VERSION ""

NS_ :

BS_:

BU_: C70 PIT IRTEMP

BO_ 384 PIT_Pressures: 8 PIT
 SG_ PIT_PressureMux M : 0|8@1+ (1,0) [0|255] "" Vector__XXX
 SG_ PIT_Pressure1 m0 : 15|16@0+ (0.01,600) [600|1200] "mbar" Vector__XXX
 SG_ PIT_Pressure2 m0 : 31|16@0+ (0.01,600) [600|1200] "mbar" Vector__XXX
 SG_ PIT_Pressure3 m0 : 47|16@0+ (0.01,600) [600|1200] "mbar" Vector__XXX
 SG_ PIT_PressureRange m0 : 56|8@1+ (1,0) [0|3] "" Vector__XXX
 SG_ PIT_Pressure4 m1 : 15|16@0+ (0.01,600) [600|1200] "mbar" Vector__XXX
 SG_ PIT_Pressure5 m1 : 31|16@0+ (0.01,600) [600|1200] "mbar" Vector__XXX
 SG_ PIT_Pressure6 m1 : 47|16@0+ (0.01,600) [600|1200] "mbar" Vector__XXX
 SG_ PIT_Temperature m1 : 56|8@1- (1,0) [0|0] "degC" Vector__XXX
 SG_ PIT_Pressure7 m2 : 15|16@0+ (0.01,600) [600|1200] "mbar" Vector__XXX
 SG_ PIT_Pressure8 m2 : 31|16@0+ (0.01,600) [600|1200] "mbar" Vector__XXX
 SG_ PIT_SensorNum m2 : 47|16@0+ (1,0) [0|0] "" Vector__XXX

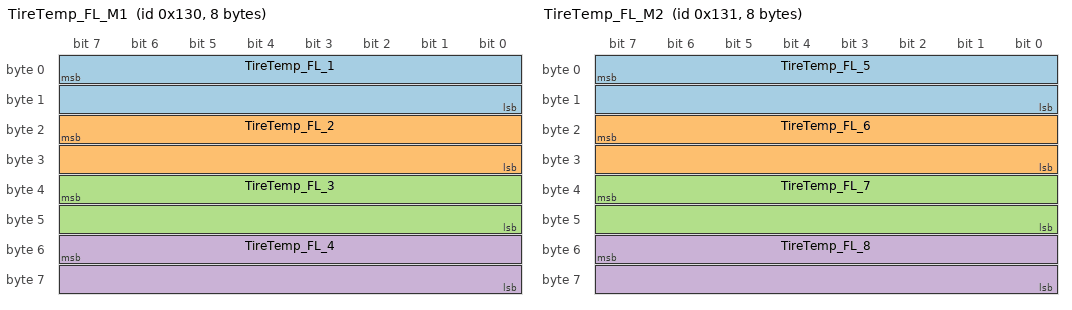
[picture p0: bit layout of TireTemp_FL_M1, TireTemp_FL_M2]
BO_ 304 TireTemp_FL_M1: 8 IRTEMP
 SG_ TireTemp_FL_1 : 7|16@0+ (0.1,-100) [-20|950] "degC" Vector__XXX
 SG_ TireTemp_FL_2 : 23|16@0+ (0.1,-100) [-20|950] "degC" Vector__XXX
 SG_ TireTemp_FL_3 : 39|16@0+ (0.1,-100) [-20|950] "degC" Vector__XXX
 SG_ TireTemp_FL_4 : 55|16@0+ (0.1,-100) [-20|950] "degC" Vector__XXX

BO_ 305 TireTemp_FL_M2: 8 IRTEMP
 SG_ TireTemp_FL_5 : 7|16@0+ (0.1,-100) [-20|950] "degC" Vector__XXX
 SG_ TireTemp_FL_6 : 23|16@0+ (0.1,-100) [-20|950] "degC" Vector__XXX
 SG_ TireTemp_FL_7 : 39|16@0+ (0.1,-100) [-20|950] "degC" Vector__XXX
 SG_ TireTemp_FL_8 : 55|16@0+ (0.1,-100) [-20|950] "degC" Vector__XXX

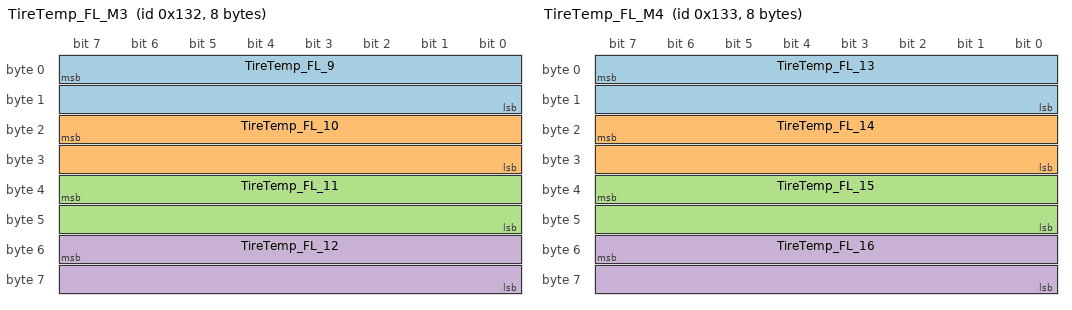
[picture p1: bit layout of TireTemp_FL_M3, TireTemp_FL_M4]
BO_ 306 TireTemp_FL_M3: 8 IRTEMP
 SG_ TireTemp_FL_9 : 7|16@0+ (0.1,-100) [-20|950] "degC" Vector__XXX
 SG_ TireTemp_FL_10 : 23|16@0+ (0.1,-100) [-20|950] "degC" Vector__XXX
 SG_ TireTemp_FL_11 : 39|16@0+ (0.1,-100) [-20|950] "degC" Vector__XXX
 SG_ TireTemp_FL_12 : 55|16@0+ (0.1,-100) [-20|950] "degC" Vector__XXX

BO_ 307 TireTemp_FL_M4: 8 IRTEMP
 SG_ TireTemp_FL_13 : 7|16@0+ (0.1,-100) [-20|950] "degC" Vector__XXX
 SG_ TireTemp_FL_14 : 23|16@0+ (0.1,-100) [-20|950] "degC" Vector__XXX
 SG_ TireTemp_FL_15 : 39|16@0+ (0.1,-100) [-20|950] "degC" Vector__XXX
 SG_ TireTemp_FL_16 : 55|16@0+ (0.1,-100) [-20|950] "degC" Vector__XXX

BO_ 308 TireTemp_FL_M5: 8 IRTEMP
 SG_ TireTemp_FL_Sensor : 7|16@0+ (0.1,-100) [-20|85] "degC" Vector__XXX

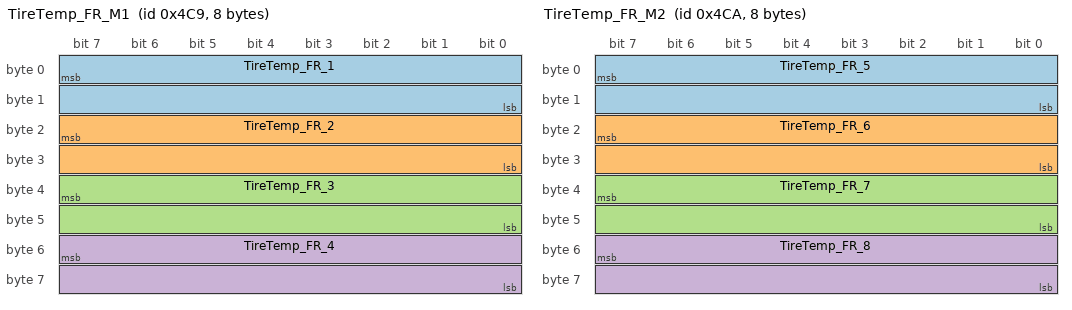
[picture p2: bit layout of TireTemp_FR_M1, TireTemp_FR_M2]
BO_ 1225 TireTemp_FR_M1: 8 IRTEMP
 SG_ TireTemp_FR_1 : 7|16@0+ (0.1,-100) [-20|950] "degC" Vector__XXX
 SG_ TireTemp_FR_2 : 23|16@0+ (0.1,-100) [-20|950] "degC" Vector__XXX
 SG_ TireTemp_FR_3 : 39|16@0+ (0.1,-100) [-20|950] "degC" Vector__XXX
 SG_ TireTemp_FR_4 : 55|16@0+ (0.1,-100) [-20|950] "degC" Vector__XXX

BO_ 1226 TireTemp_FR_M2: 8 IRTEMP
 SG_ TireTemp_FR_5 : 7|16@0+ (0.1,-100) [-20|950] "degC" Vector__XXX
 SG_ TireTemp_FR_6 : 23|16@0+ (0.1,-100) [-20|950] "degC" Vector__XXX
 SG_ TireTemp_FR_7 : 39|16@0+ (0.1,-100) [-20|950] "degC" Vector__XXX
 SG_ TireTemp_FR_8 : 55|16@0+ (0.1,-100) [-20|950] "degC" Vector__XXX

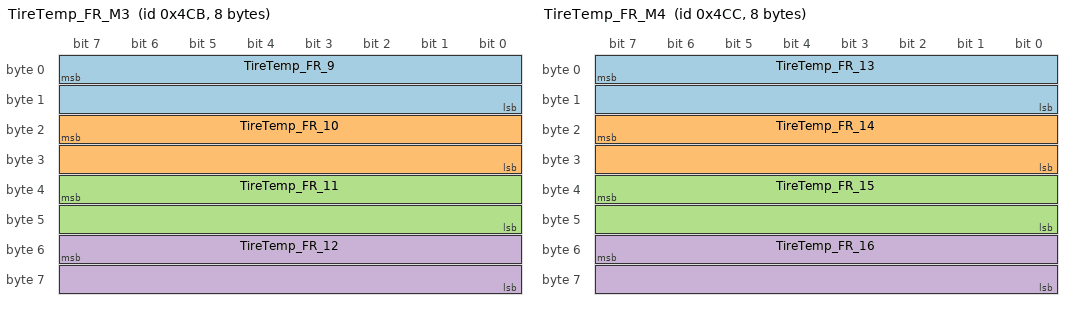
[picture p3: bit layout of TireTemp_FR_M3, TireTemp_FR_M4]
BO_ 1227 TireTemp_FR_M3: 8 IRTEMP
 SG_ TireTemp_FR_9 : 7|16@0+ (0.1,-100) [-20|950] "degC" Vector__XXX
 SG_ TireTemp_FR_10 : 23|16@0+ (0.1,-100) [-20|950] "degC" Vector__XXX
 SG_ TireTemp_FR_11 : 39|16@0+ (0.1,-100) [-20|950] "degC" Vector__XXX
 SG_ TireTemp_FR_12 : 55|16@0+ (0.1,-100) [-20|950] "degC" Vector__XXX

BO_ 1228 TireTemp_FR_M4: 8 IRTEMP
 SG_ TireTemp_FR_13 : 7|16@0+ (0.1,-100) [-20|950] "degC" Vector__XXX
 SG_ TireTemp_FR_14 : 23|16@0+ (0.1,-100) [-20|950] "degC" Vector__XXX
 SG_ TireTemp_FR_15 : 39|16@0+ (0.1,-100) [-20|950] "degC" Vector__XXX
 SG_ TireTemp_FR_16 : 55|16@0+ (0.1,-100) [-20|950] "degC" Vector__XXX

BO_ 1229 TireTemp_FR_M5: 8 IRTEMP
 SG_ TireTemp_FR_Sensor : 7|16@0+ (0.1,-100) [-20|85] "degC" Vector__XXX

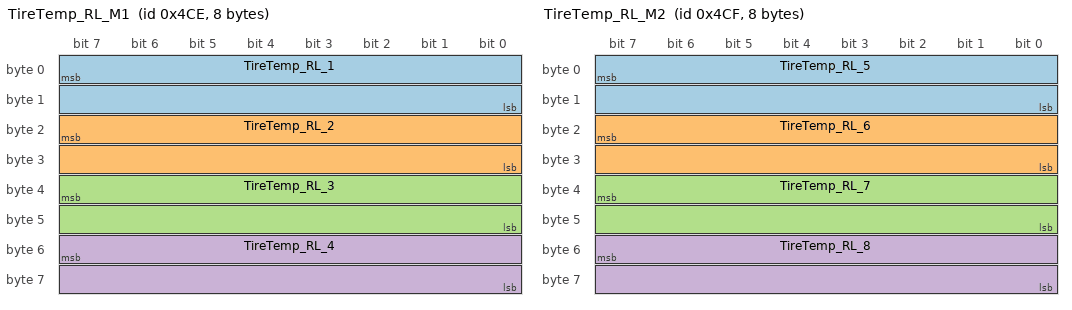
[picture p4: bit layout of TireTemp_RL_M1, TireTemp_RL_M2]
BO_ 1230 TireTemp_RL_M1: 8 IRTEMP
 SG_ TireTemp_RL_1 : 7|16@0+ (0.1,-100) [-20|950] "degC" Vector__XXX
 SG_ TireTemp_RL_2 : 23|16@0+ (0.1,-100) [-20|950] "degC" Vector__XXX
 SG_ TireTemp_RL_3 : 39|16@0+ (0.1,-100) [-20|950] "degC" Vector__XXX
 SG_ TireTemp_RL_4 : 55|16@0+ (0.1,-100) [-20|950] "degC" Vector__XXX

BO_ 1231 TireTemp_RL_M2: 8 IRTEMP
 SG_ TireTemp_RL_5 : 7|16@0+ (0.1,-100) [-20|950] "degC" Vector__XXX
 SG_ TireTemp_RL_6 : 23|16@0+ (0.1,-100) [-20|950] "degC" Vector__XXX
 SG_ TireTemp_RL_7 : 39|16@0+ (0.1,-100) [-20|950] "degC" Vector__XXX
 SG_ TireTemp_RL_8 : 55|16@0+ (0.1,-100) [-20|950] "degC" Vector__XXX

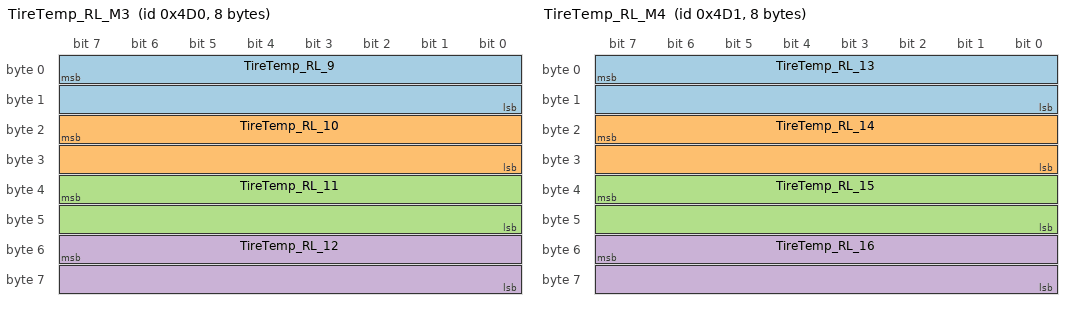
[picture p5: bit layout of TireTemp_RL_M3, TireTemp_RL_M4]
BO_ 1232 TireTemp_RL_M3: 8 IRTEMP
 SG_ TireTemp_RL_9 : 7|16@0+ (0.1,-100) [-20|950] "degC" Vector__XXX
 SG_ TireTemp_RL_10 : 23|16@0+ (0.1,-100) [-20|950] "degC" Vector__XXX
 SG_ TireTemp_RL_11 : 39|16@0+ (0.1,-100) [-20|950] "degC" Vector__XXX
 SG_ TireTemp_RL_12 : 55|16@0+ (0.1,-100) [-20|950] "degC" Vector__XXX

BO_ 1233 TireTemp_RL_M4: 8 IRTEMP
 SG_ TireTemp_RL_13 : 7|16@0+ (0.1,-100) [-20|950] "degC" Vector__XXX
 SG_ TireTemp_RL_14 : 23|16@0+ (0.1,-100) [-20|950] "degC" Vector__XXX
 SG_ TireTemp_RL_15 : 39|16@0+ (0.1,-100) [-20|950] "degC" Vector__XXX
 SG_ TireTemp_RL_16 : 55|16@0+ (0.1,-100) [-20|950] "degC" Vector__XXX

BO_ 1234 TireTemp_RL_M5: 8 IRTEMP
 SG_ TireTemp_RL_Sensor : 7|16@0+ (0.1,-100) [-20|85] "degC" Vector__XXX

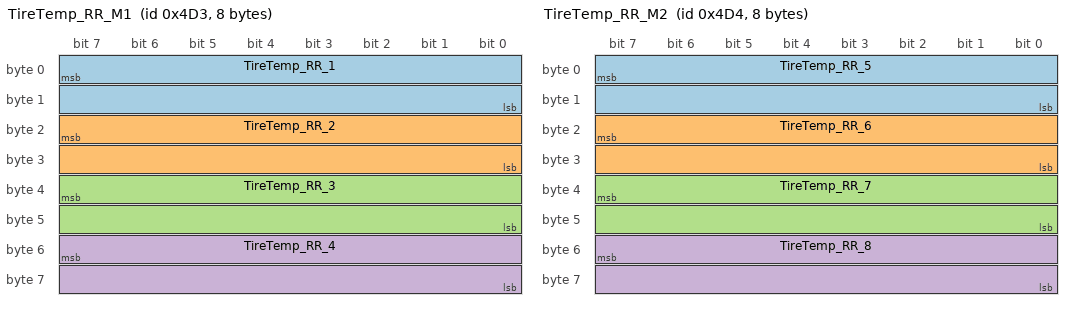
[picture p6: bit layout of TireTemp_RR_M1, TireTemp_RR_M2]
BO_ 1235 TireTemp_RR_M1: 8 IRTEMP
 SG_ TireTemp_RR_1 : 7|16@0+ (0.1,-100) [-20|950] "degC" Vector__XXX
 SG_ TireTemp_RR_2 : 23|16@0+ (0.1,-100) [-20|950] "degC" Vector__XXX
 SG_ TireTemp_RR_3 : 39|16@0+ (0.1,-100) [-20|950] "degC" Vector__XXX
 SG_ TireTemp_RR_4 : 55|16@0+ (0.1,-100) [-20|950] "degC" Vector__XXX

BO_ 1236 TireTemp_RR_M2: 8 IRTEMP
 SG_ TireTemp_RR_5 : 7|16@0+ (0.1,-100) [-20|950] "degC" Vector__XXX
 SG_ TireTemp_RR_6 : 23|16@0+ (0.1,-100) [-20|950] "degC" Vector__XXX
 SG_ TireTemp_RR_7 : 39|16@0+ (0.1,-100) [-20|950] "degC" Vector__XXX
 SG_ TireTemp_RR_8 : 55|16@0+ (0.1,-100) [-20|950] "degC" Vector__XXX

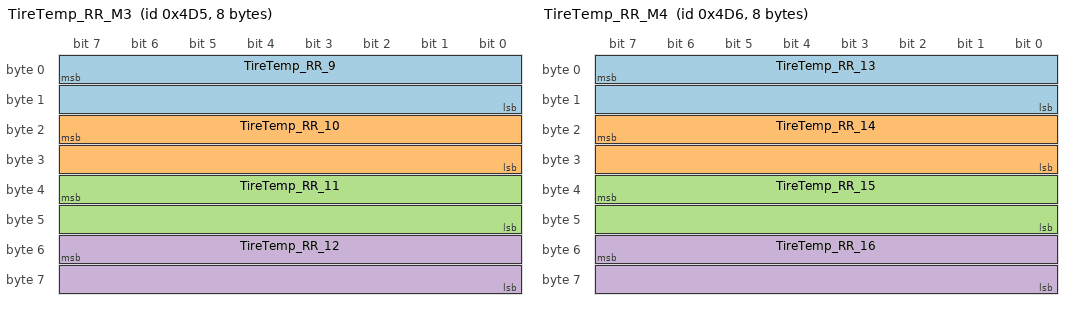
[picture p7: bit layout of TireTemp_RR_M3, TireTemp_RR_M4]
BO_ 1237 TireTemp_RR_M3: 8 IRTEMP
 SG_ TireTemp_RR_9 : 7|16@0+ (0.1,-100) [-20|950] "degC" Vector__XXX
 SG_ TireTemp_RR_10 : 23|16@0+ (0.1,-100) [-20|950] "degC" Vector__XXX
 SG_ TireTemp_RR_11 : 39|16@0+ (0.1,-100) [-20|950] "degC" Vector__XXX
 SG_ TireTemp_RR_12 : 55|16@0+ (0.1,-100) [-20|950] "degC" Vector__XXX

BO_ 1238 TireTemp_RR_M4: 8 IRTEMP
 SG_ TireTemp_RR_13 : 7|16@0+ (0.1,-100) [-20|950] "degC" Vector__XXX
 SG_ TireTemp_RR_14 : 23|16@0+ (0.1,-100) [-20|950] "degC" Vector__XXX
 SG_ TireTemp_RR_15 : 39|16@0+ (0.1,-100) [-20|950] "degC" Vector__XXX
 SG_ TireTemp_RR_16 : 55|16@0+ (0.1,-100) [-20|950] "degC" Vector__XXX

BO_ 1239 TireTemp_RR_M5: 8 IRTEMP
 SG_ TireTemp_RR_Sensor : 7|16@0+ (0.1,-100) [-20|85] "degC" Vector__XXX

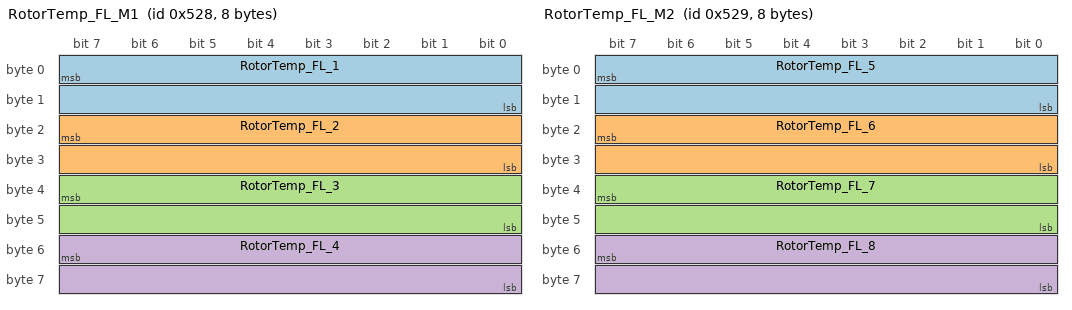
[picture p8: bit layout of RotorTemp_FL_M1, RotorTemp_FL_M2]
BO_ 1320 RotorTemp_FL_M1: 8 IRTEMP
 SG_ RotorTemp_FL_1 : 7|16@0+ (0.1,-100) [-20|950] "degC" Vector__XXX
 SG_ RotorTemp_FL_2 : 23|16@0+ (0.1,-100) [-20|950] "degC" Vector__XXX
 SG_ RotorTemp_FL_3 : 39|16@0+ (0.1,-100) [-20|950] "degC" Vector__XXX
 SG_ RotorTemp_FL_4 : 55|16@0+ (0.1,-100) [-20|950] "degC" Vector__XXX

BO_ 1321 RotorTemp_FL_M2: 8 IRTEMP
 SG_ RotorTemp_FL_5 : 7|16@0+ (0.1,-100) [-20|950] "degC" Vector__XXX
 SG_ RotorTemp_FL_6 : 23|16@0+ (0.1,-100) [-20|950] "degC" Vector__XXX
 SG_ RotorTemp_FL_7 : 39|16@0+ (0.1,-100) [-20|950] "degC" Vector__XXX
 SG_ RotorTemp_FL_8 : 55|16@0+ (0.1,-100) [-20|950] "degC" Vector__XXX

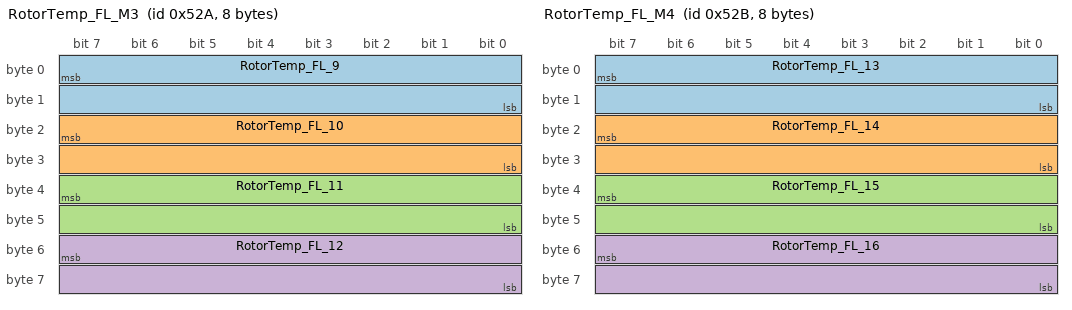
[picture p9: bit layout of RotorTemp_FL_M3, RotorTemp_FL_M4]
BO_ 1322 RotorTemp_FL_M3: 8 IRTEMP
 SG_ RotorTemp_FL_9 : 7|16@0+ (0.1,-100) [-20|950] "degC" Vector__XXX
 SG_ RotorTemp_FL_10 : 23|16@0+ (0.1,-100) [-20|950] "degC" Vector__XXX
 SG_ RotorTemp_FL_11 : 39|16@0+ (0.1,-100) [-20|950] "degC" Vector__XXX
 SG_ RotorTemp_FL_12 : 55|16@0+ (0.1,-100) [-20|950] "degC" Vector__XXX

BO_ 1323 RotorTemp_FL_M4: 8 IRTEMP
 SG_ RotorTemp_FL_13 : 7|16@0+ (0.1,-100) [-20|950] "degC" Vector__XXX
 SG_ RotorTemp_FL_14 : 23|16@0+ (0.1,-100) [-20|950] "degC" Vector__XXX
 SG_ RotorTemp_FL_15 : 39|16@0+ (0.1,-100) [-20|950] "degC" Vector__XXX
 SG_ RotorTemp_FL_16 : 55|16@0+ (0.1,-100) [-20|950] "degC" Vector__XXX

BO_ 1324 RotorTemp_FL_M5: 8 IRTEMP
 SG_ RotorTemp_FL_Sensor : 7|16@0+ (0.1,-100) [-20|85] "degC" Vector__XXX

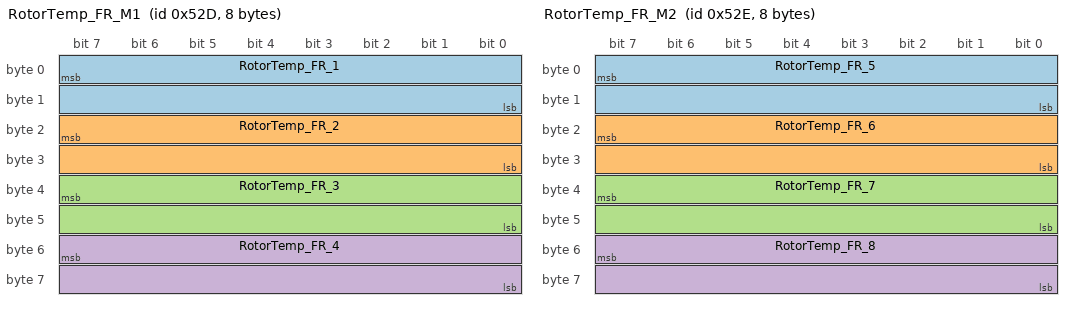
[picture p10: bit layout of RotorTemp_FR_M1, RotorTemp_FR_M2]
BO_ 1325 RotorTemp_FR_M1: 8 IRTEMP
 SG_ RotorTemp_FR_1 : 7|16@0+ (0.1,-100) [-20|950] "degC" Vector__XXX
 SG_ RotorTemp_FR_2 : 23|16@0+ (0.1,-100) [-20|950] "degC" Vector__XXX
 SG_ RotorTemp_FR_3 : 39|16@0+ (0.1,-100) [-20|950] "degC" Vector__XXX
 SG_ RotorTemp_FR_4 : 55|16@0+ (0.1,-100) [-20|950] "degC" Vector__XXX

BO_ 1326 RotorTemp_FR_M2: 8 IRTEMP
 SG_ RotorTemp_FR_5 : 7|16@0+ (0.1,-100) [-20|950] "degC" Vector__XXX
 SG_ RotorTemp_FR_6 : 23|16@0+ (0.1,-100) [-20|950] "degC" Vector__XXX
 SG_ RotorTemp_FR_7 : 39|16@0+ (0.1,-100) [-20|950] "degC" Vector__XXX
 SG_ RotorTemp_FR_8 : 55|16@0+ (0.1,-100) [-20|950] "degC" Vector__XXX

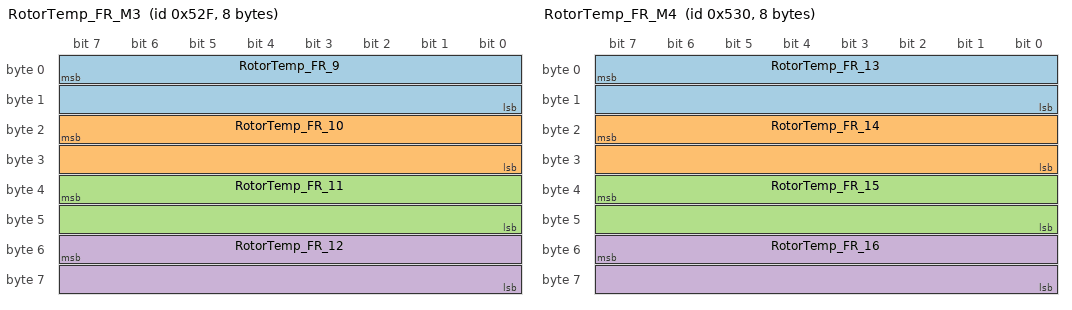
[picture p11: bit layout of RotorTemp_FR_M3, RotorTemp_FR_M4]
BO_ 1327 RotorTemp_FR_M3: 8 IRTEMP
 SG_ RotorTemp_FR_9 : 7|16@0+ (0.1,-100) [-20|950] "degC" Vector__XXX
 SG_ RotorTemp_FR_10 : 23|16@0+ (0.1,-100) [-20|950] "degC" Vector__XXX
 SG_ RotorTemp_FR_11 : 39|16@0+ (0.1,-100) [-20|950] "degC" Vector__XXX
 SG_ RotorTemp_FR_12 : 55|16@0+ (0.1,-100) [-20|950] "degC" Vector__XXX

BO_ 1328 RotorTemp_FR_M4: 8 IRTEMP
 SG_ RotorTemp_FR_13 : 7|16@0+ (0.1,-100) [-20|950] "degC" Vector__XXX
 SG_ RotorTemp_FR_14 : 23|16@0+ (0.1,-100) [-20|950] "degC" Vector__XXX
 SG_ RotorTemp_FR_15 : 39|16@0+ (0.1,-100) [-20|950] "degC" Vector__XXX
 SG_ RotorTemp_FR_16 : 55|16@0+ (0.1,-100) [-20|950] "degC" Vector__XXX

BO_ 1329 RotorTemp_FR_M5: 8 IRTEMP
 SG_ RotorTemp_FR_Sensor : 7|16@0+ (0.1,-100) [-20|85] "degC" Vector__XXX

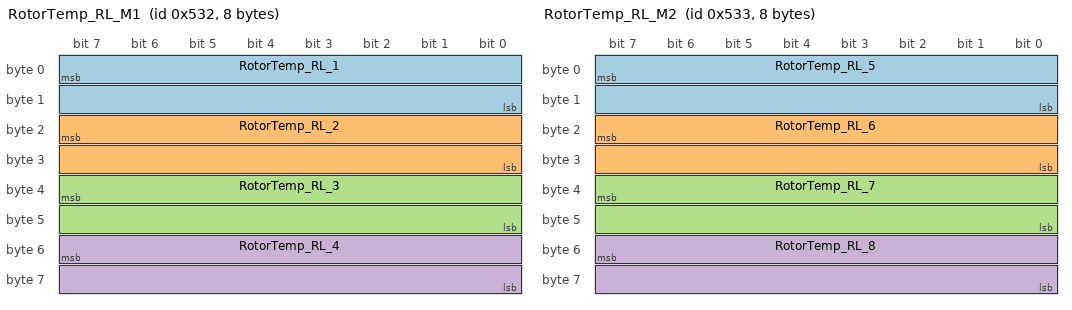
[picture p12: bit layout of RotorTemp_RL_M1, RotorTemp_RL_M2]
BO_ 1330 RotorTemp_RL_M1: 8 IRTEMP
 SG_ RotorTemp_RL_1 : 7|16@0+ (0.1,-100) [-20|950] "degC" Vector__XXX
 SG_ RotorTemp_RL_2 : 23|16@0+ (0.1,-100) [-20|950] "degC" Vector__XXX
 SG_ RotorTemp_RL_3 : 39|16@0+ (0.1,-100) [-20|950] "degC" Vector__XXX
 SG_ RotorTemp_RL_4 : 55|16@0+ (0.1,-100) [-20|950] "degC" Vector__XXX

BO_ 1331 RotorTemp_RL_M2: 8 IRTEMP
 SG_ RotorTemp_RL_5 : 7|16@0+ (0.1,-100) [-20|950] "degC" Vector__XXX
 SG_ RotorTemp_RL_6 : 23|16@0+ (0.1,-100) [-20|950] "degC" Vector__XXX
 SG_ RotorTemp_RL_7 : 39|16@0+ (0.1,-100) [-20|950] "degC" Vector__XXX
 SG_ RotorTemp_RL_8 : 55|16@0+ (0.1,-100) [-20|950] "degC" Vector__XXX

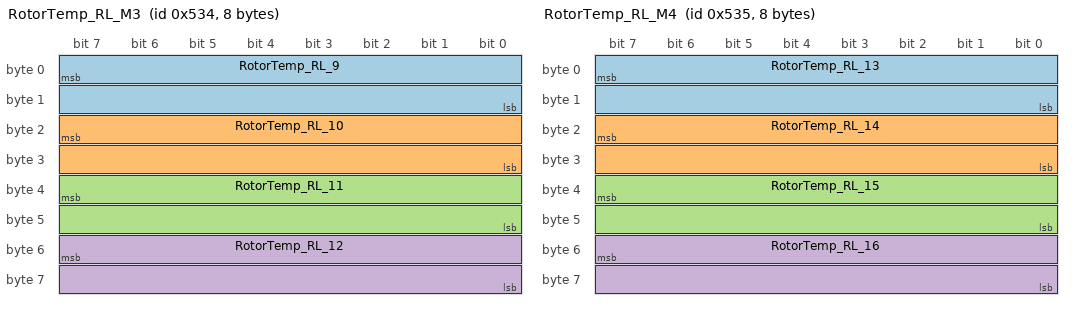
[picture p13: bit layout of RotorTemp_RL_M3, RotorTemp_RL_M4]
BO_ 1332 RotorTemp_RL_M3: 8 IRTEMP
 SG_ RotorTemp_RL_9 : 7|16@0+ (0.1,-100) [-20|950] "degC" Vector__XXX
 SG_ RotorTemp_RL_10 : 23|16@0+ (0.1,-100) [-20|950] "degC" Vector__XXX
 SG_ RotorTemp_RL_11 : 39|16@0+ (0.1,-100) [-20|950] "degC" Vector__XXX
 SG_ RotorTemp_RL_12 : 55|16@0+ (0.1,-100) [-20|950] "degC" Vector__XXX

BO_ 1333 RotorTemp_RL_M4: 8 IRTEMP
 SG_ RotorTemp_RL_13 : 7|16@0+ (0.1,-100) [-20|950] "degC" Vector__XXX
 SG_ RotorTemp_RL_14 : 23|16@0+ (0.1,-100) [-20|950] "degC" Vector__XXX
 SG_ RotorTemp_RL_15 : 39|16@0+ (0.1,-100) [-20|950] "degC" Vector__XXX
 SG_ RotorTemp_RL_16 : 55|16@0+ (0.1,-100) [-20|950] "degC" Vector__XXX

BO_ 1334 RotorTemp_RL_M5: 8 IRTEMP
 SG_ RotorTemp_RL_Sensor : 7|16@0+ (0.1,-100) [-20|85] "degC" Vector__XXX

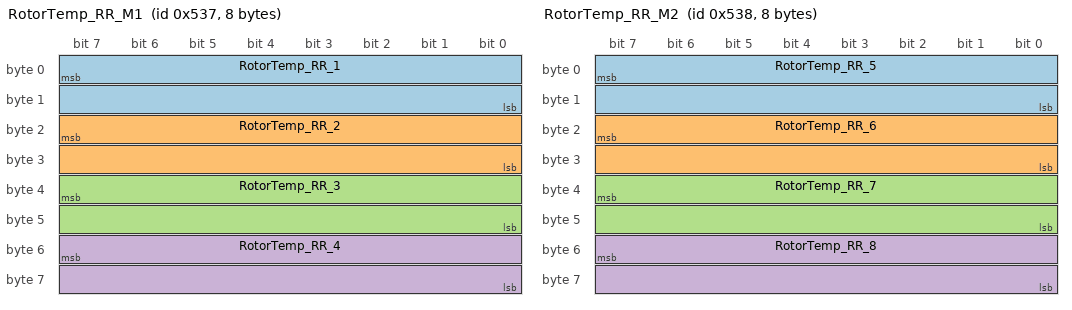
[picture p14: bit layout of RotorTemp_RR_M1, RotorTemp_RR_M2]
BO_ 1335 RotorTemp_RR_M1: 8 IRTEMP
 SG_ RotorTemp_RR_1 : 7|16@0+ (0.1,-100) [-20|950] "degC" Vector__XXX
 SG_ RotorTemp_RR_2 : 23|16@0+ (0.1,-100) [-20|950] "degC" Vector__XXX
 SG_ RotorTemp_RR_3 : 39|16@0+ (0.1,-100) [-20|950] "degC" Vector__XXX
 SG_ RotorTemp_RR_4 : 55|16@0+ (0.1,-100) [-20|950] "degC" Vector__XXX

BO_ 1336 RotorTemp_RR_M2: 8 IRTEMP
 SG_ RotorTemp_RR_5 : 7|16@0+ (0.1,-100) [-20|950] "degC" Vector__XXX
 SG_ RotorTemp_RR_6 : 23|16@0+ (0.1,-100) [-20|950] "degC" Vector__XXX
 SG_ RotorTemp_RR_7 : 39|16@0+ (0.1,-100) [-20|950] "degC" Vector__XXX
 SG_ RotorTemp_RR_8 : 55|16@0+ (0.1,-100) [-20|950] "degC" Vector__XXX

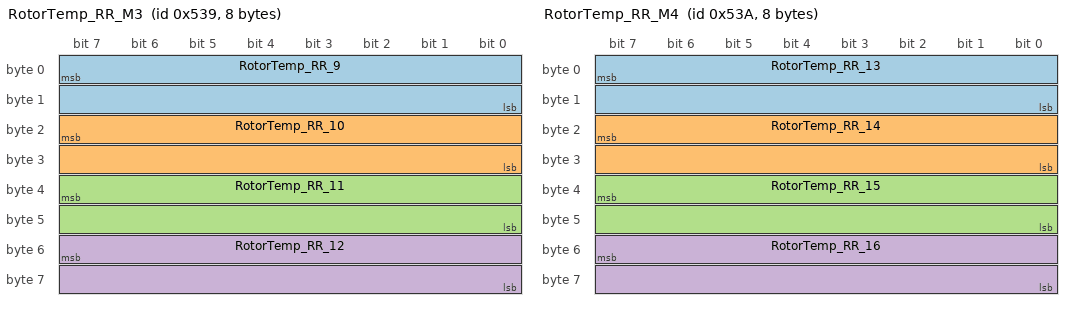
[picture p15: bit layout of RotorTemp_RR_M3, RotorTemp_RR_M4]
BO_ 1337 RotorTemp_RR_M3: 8 IRTEMP
 SG_ RotorTemp_RR_9 : 7|16@0+ (0.1,-100) [-20|950] "degC" Vector__XXX
 SG_ RotorTemp_RR_10 : 23|16@0+ (0.1,-100) [-20|950] "degC" Vector__XXX
 SG_ RotorTemp_RR_11 : 39|16@0+ (0.1,-100) [-20|950] "degC" Vector__XXX
 SG_ RotorTemp_RR_12 : 55|16@0+ (0.1,-100) [-20|950] "degC" Vector__XXX

BO_ 1338 RotorTemp_RR_M4: 8 IRTEMP
 SG_ RotorTemp_RR_13 : 7|16@0+ (0.1,-100) [-20|950] "degC" Vector__XXX
 SG_ RotorTemp_RR_14 : 23|16@0+ (0.1,-100) [-20|950] "degC" Vector__XXX
 SG_ RotorTemp_RR_15 : 39|16@0+ (0.1,-100) [-20|950] "degC" Vector__XXX
 SG_ RotorTemp_RR_16 : 55|16@0+ (0.1,-100) [-20|950] "degC" Vector__XXX

BO_ 1339 RotorTemp_RR_M5: 8 IRTEMP
 SG_ RotorTemp_RR_Sensor : 7|16@0+ (0.1,-100) [-20|85] "degC" Vector__XXX

BO_ 400 VectorNav0: 8 VectorNav
 SG_ VectorNav_AccelX : 0|32@1+ (1,0) [0|0] "m/s^2" Vector__XXX
 SG_ VectorNav_AccelY : 32|32@1+ (1,0) [0|0] "m/s^2" Vector__XXX

BO_ 401 VectorNav1: 8 VectorNav
 SG_ VectorNav_AccelZ : 0|32@1+ (1,0) [0|0] "m/s^2" Vector__XXX
 SG_ VectorNav_AngularRateX : 32|32@1+ (1,0) [0|0] "rad/s" Vector__XXX

BO_ 402 VectorNav2: 8 VectorNav
 SG_ VectorNav_AngularRateY : 0|32@1+ (1,0) [0|0] "rad/s" Vector__XXX
 SG_ VectorNav_AngularRateZ : 32|32@1+ (1,0) [0|0] "rad/s" Vector__XXX

BO_ 403 VectorNav3: 8 VectorNav
 SG_ VectorNav_PosLlaL : 0|64@1+ (1,0) [0|0] "deg" Vector__XXX

BO_ 404 VectorNav4: 8 VectorNav
 SG_ VectorNav_PosLlaO : 0|64@1+ (1,0) [0|0] "deg" Vector__XXX

BO_ 405 VectorNav5: 8 VectorNav
 SG_ VectorNav_PosLlaA : 0|64@1+ (1,0) [0|0] "m" Vector__XXX

BO_ 406 VectorNav6: 8 VectorNav
 SG_ VectorNav_VelBodyX : 0|32@1+ (1,0) [0|0] "m/s" Vector__XXX
 SG_ VectorNav_VelBodyY : 32|32@1+ (1,0) [0|0] "m/s" Vector__XXX

BO_ 407 VectorNav7: 8 VectorNav
 SG_ VectorNav_VelBodyZ : 0|32@1+ (1,0) [0|0] "m/s" Vector__XXX
 SG_ VectorNav_YprY : 32|32@1+ (1,0) [0|0] "deg" Vector__XXX

BO_ 408 VectorNav8: 8 VectorNav
 SG_ VectorNav_YprP : 0|32@1+ (1,0) [0|0] "deg" Vector__XXX
 SG_ VectorNav_YprR : 32|32@1+ (1,0) [0|0] "deg" Vector__XXX

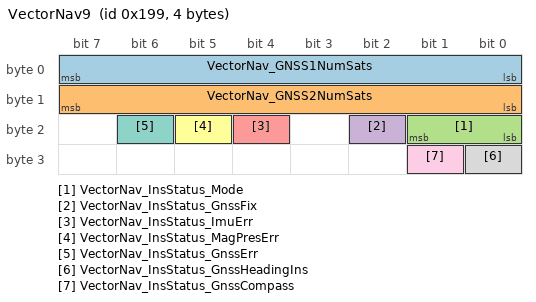
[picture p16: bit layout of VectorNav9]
BO_ 409 VectorNav9: 4 VectorNav
 SG_ VectorNav_GNSS1NumSats : 0|8@1+ (1,0) [0|255] "" Vector__XXX
 SG_ VectorNav_GNSS2NumSats : 8|8@1+ (1,0) [0|255] "" Vector__XXX
 SG_ VectorNav_InsStatus_Mode : 16|2@1+ (1,0) [0|2] "" Vector__XXX
 SG_ VectorNav_InsStatus_GnssFix : 18|1@1+ (1,0) [0|1] "" Vector__XXX
 SG_ VectorNav_InsStatus_ImuErr : 20|1@1+ (1,0) [0|1] "" Vector__XXX
 SG_ VectorNav_InsStatus_MagPresErr : 21|1@1+ (1,0) [0|1] "" Vector__XXX
 SG_ VectorNav_InsStatus_GnssErr : 22|1@1+ (1,0) [0|1] "" Vector__XXX
 SG_ VectorNav_InsStatus_GnssHeadingIns : 24|1@1+ (1,0) [0|1] "" Vector__XXX
 SG_ VectorNav_InsStatus_GnssCompass : 25|1@1+ (1,0) [0|1] "" Vector__XXX

BO_ 410 VectorNav10: 8 VectorNav
 SG_ VectorNav_BodySlip : 0|32@1+ (1,0) [0|0] "" Vector__XXX

BO_ 500 SSDB_suspension_front: 3 SSDB
 SG_ SSDB_suspension_FL : 0|12@1+ (1,0) [0|4095] "" Vector__XXX
 SG_ SSDB_suspension_FR : 12|12@1+ (1,0) [0|4095] "" Vector__XXX

BO_ 501 SSDB_suspension_rear: 3 SSDB
 SG_ SSDB_suspension_RL : 0|12@1+ (1,0) [0|4095] "" Vector__XXX
 SG_ SSDB_suspension_RR : 12|12@1+ (1,0) [0|4095] "" Vector__XXX

BO_ 600 FDL_Status: 8 FDL
 SG_ FDL_ASMS : 0|1@1+ (1,0) [0|0] "" Vector__XXX

BO_ 2566845491 TPMS_TirePressure: 8 TPMS
 SG_ TPMS_TireNum M : 7|8@0+ (1,0) [1|4] "" Vector__XXX
 SG_ TPMS_T1_TirePressure m1 : 15|16@0+ (1,0) [0|0] "kPa" Vector__XXX
 SG_ TPMS_T1_TireTemp m1 : 31|8@0+ (1,0) [0|0] "degC" Vector__XXX
 SG_ TPMS_T1_Voltage m1 : 39|8@0+ (0.1,0) [0|0] "V" Vector__XXX
 SG_ TPMS_T1_Leak m1 : 40|1@0+ (1,0) [0|0] "" Vector__XXX
 SG_ TPMS_T1_MinusTemp m1 : 44|1@0+ (1,0) [0|0] "" Vector__XXX
 SG_ TPMS_T1_Error m1 : 45|1@0+ (1,0) [0|0] "" Vector__XXX
 SG_ TPMS_T2_TirePressure m2 : 15|16@0+ (1,0) [0|0] "kPa" Vector__XXX
 SG_ TPMS_T2_TireTemp m2 : 31|8@0+ (1,0) [0|0] "degC" Vector__XXX
 SG_ TPMS_T2_Voltage m2 : 39|8@0+ (0.1,0) [0|0] "V" Vector__XXX
 SG_ TPMS_T2_Leak m2 : 40|1@0+ (1,0) [0|0] "" Vector__XXX
 SG_ TPMS_T2_MinusTemp m2 : 44|1@0+ (1,0) [0|0] "" Vector__XXX
 SG_ TPMS_T2_Error m2 : 45|1@0+ (1,0) [0|0] "" Vector__XXX
 SG_ TPMS_T3_TirePressure m3 : 15|16@0+ (1,0) [0|0] "kPa" Vector__XXX
 SG_ TPMS_T3_TireTemp m3 : 31|8@0+ (1,0) [0|0] "degC" Vector__XXX
 SG_ TPMS_T3_Voltage m3 : 39|8@0+ (0.1,0) [0|0] "V" Vector__XXX
 SG_ TPMS_T3_Leak m3 : 40|1@0+ (1,0) [0|0] "" Vector__XXX
 SG_ TPMS_T3_MinusTemp m3 : 44|1@0+ (1,0) [0|0] "" Vector__XXX
 SG_ TPMS_T3_Error m3 : 45|1@0+ (1,0) [0|0] "" Vector__XXX
 SG_ TPMS_T4_TirePressure m4 : 15|16@0+ (1,0) [0|0] "kPa" Vector__XXX
 SG_ TPMS_T4_TireTemp m4 : 31|8@0+ (1,0) [0|0] "degC" Vector__XXX
 SG_ TPMS_T4_Voltage m4 : 39|8@0+ (0.1,0) [0|0] "V" Vector__XXX
 SG_ TPMS_T4_Leak m4 : 40|1@0+ (1,0) [0|0] "" Vector__XXX
 SG_ TPMS_T4_MinusTemp m4 : 44|1@0+ (1,0) [0|0] "" Vector__XXX
 SG_ TPMS_T4_Error m4 : 45|1@0+ (1,0) [0|0] "" Vector__XXX

CM_ BU_ FDL "Front driverless actuation";
CM_ BU_ C70 "Bosch C70 Data Logger";
CM_ BU_ PIT "EvoScann P8-A Pressure Sensor";
CM_ BU_ IRTEMP "Izze IRTS-60 v2 IR Temperature Sensors";
CM_ BU_ VectorNav "VectorNav IMU";
CM_ BU_ SSDB "SSDB";

SIG_VALTYPE_ 400 VectorNav_AccelX : 1;
SIG_VALTYPE_ 400 VectorNav_AccelY : 1;
SIG_VALTYPE_ 401 VectorNav_AccelZ : 1;
SIG_VALTYPE_ 401 VectorNav_AngularRateX : 1;
SIG_VALTYPE_ 402 VectorNav_AngularRateY : 1;
SIG_VALTYPE_ 402 VectorNav_AngularRateZ : 1;
SIG_VALTYPE_ 403 VectorNav_PosLlaL : 2;
SIG_VALTYPE_ 404 VectorNav_PosLlaO : 2;
SIG_VALTYPE_ 405 VectorNav_PosLlaA : 2;
SIG_VALTYPE_ 406 VectorNav_VelBodyX : 1;
SIG_VALTYPE_ 406 VectorNav_VelBodyY : 1;
SIG_VALTYPE_ 407 VectorNav_VelBodyZ : 1;
SIG_VALTYPE_ 407 VectorNav_YprY : 1;
SIG_VALTYPE_ 408 VectorNav_YprP : 1;
SIG_VALTYPE_ 408 VectorNav_YprR : 1;
SIG_VALTYPE_ 410 VectorNav_BodySlip : 1;
